# MKL02Z4 register map
Vendor: Freescale Semiconductor, Inc.; Series: Kinetis_L; File version: 1.6
CPU: CM0PLUS r0p0, little endian, no MPU, no FPU, VTOR, 2 interrupt priority bits
Registers are 32-bit, read-write, reset 0x0 unless marked. A register's access mark holds for its fields unless they carry their own. Offsets are from the block's base; [hi:lo] are bit positions; {n}, {i} and the like mark numbered series; 'fields as' and 'values as' point back to an identical list.

## PORTB — Pin Control and Interrupts
Base 0x4004A000; register names take the prefix PORTB_
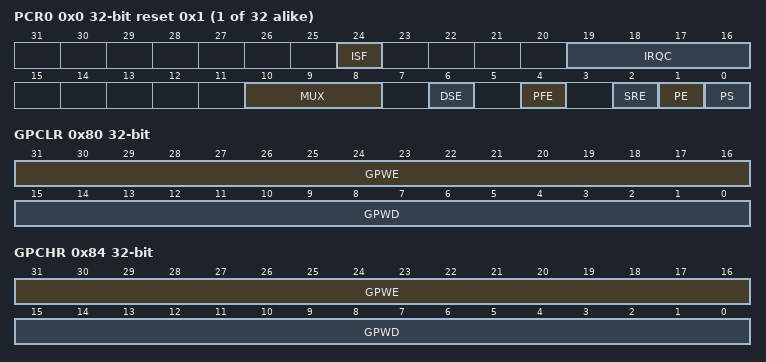
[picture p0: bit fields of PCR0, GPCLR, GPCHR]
{0x0+4i} PCR{i} (i=0..31) reset 0x1 — Pin Control Register n
  [24] ISF — Interrupt Status Flag
    0=Configured interrupt is not detected; 1=Configured interrupt is detected. The flag remains set until a logic one is written to the flag. If the pin is configured for a level sensitive interrupt and the pin remains asserted, then the flag is set again immediately after it is cleared.
  [19:16] IRQC — Interrupt Configuration
    0=Interrupt request disabled; 8=Interrupt when logic zero; 9=Interrupt on rising edge; 10=Interrupt on falling edge; 11=Interrupt on either edge; 12=Interrupt when logic one
  [10:8] MUX — Pin Mux Control
    0=Pin disabled (analog); 1=Alternative 1 (GPIO); {v}=Alternative {v} (chip-specific) (v=2..7)
  [6] DSE — Drive Strength Enable
    0=Low drive strength is configured on the corresponding pin, if pin is configured as a digital output; 1=High drive strength is configured on the corresponding pin, if pin is configured as a digital output
  [4] PFE — Passive Filter Enable
    0=Passive input filter is disabled on the corresponding pin; 1=Passive input filter is enabled on the corresponding pin, if the pin is configured as a digital input. Refer to the device data sheet for filter characteristics.
  [2] SRE — Slew Rate Enable
    0=Fast slew rate is configured on the corresponding pin, if the pin is configured as a digital output; 1=Slow slew rate is configured on the corresponding pin, if the pin is configured as a digital output
  [1] PE — Pull Enable
    0=Internal pullup or pulldown resistor is not enabled on the corresponding pin; 1=Internal pullup or pulldown resistor is enabled on the corresponding pin, if the pin is configured as a digital input
  [0] PS — Pull Select
    0=Internal pulldown resistor is enabled on the corresponding pin, if the corresponding Port Pull Enable field is set; 1=Internal pullup resistor is enabled on the corresponding pin, if the corresponding Port Pull Enable field is set
0x80 GPCLR wo — Global Pin Control Low Register
  [31:16] GPWE — Global Pin Write Enable
    0=Corresponding Pin Control Register is not updated with the value in GPWD; 1=Corresponding Pin Control Register is updated with the value in GPWD
  [15:0] GPWD — Global Pin Write Data
0x84 GPCHR wo — Global Pin Control High Register
  fields as GPCLR
0xA0 ISFR — Interrupt Status Flag Register
  [31:0] ISF — Interrupt Status Flag
    values as PCR0.ISF

## OSC0 — Oscillator
Base 0x40065000; register names take the prefix OSC0_
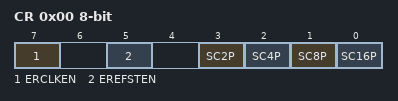
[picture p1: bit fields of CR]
0x00 CR 8-bit — OSC Control Register
  [7] ERCLKEN — External Reference Enable
    0=External reference clock is inactive; 1=External reference clock is enabled
  [5] EREFSTEN — External Reference Stop Enable
    0=External reference clock is disabled in Stop mode; 1=External reference clock stays enabled in Stop mode if ERCLKEN is set before entering Stop mode
  [3] SC2P — Oscillator 2 pF Capacitor Load Configure
    0=Disable the selection; 1=Add 2 pF capacitor to the oscillator load
  [2] SC4P — Oscillator 4 pF Capacitor Load Configure
    0=Disable the selection; 1=Add 4 pF capacitor to the oscillator load
  [1] SC8P — Oscillator 8 pF Capacitor Load Configure
    0=Disable the selection; 1=Add 8 pF capacitor to the oscillator load
  [0] SC16P — Oscillator 16 pF Capacitor Load Configure
    0=Disable the selection; 1=Add 16 pF capacitor to the oscillator load

## I2C0 — Inter-Integrated Circuit
Base 0x40066000; register names take the prefix I2C0_
0x00 A1 8-bit — I2C Address Register 1
  [7:1] AD — Address
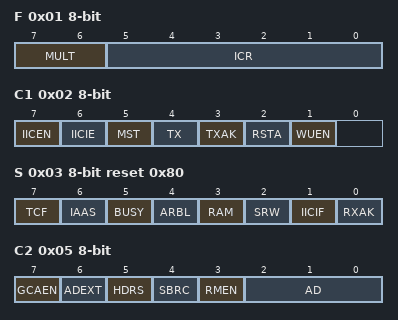
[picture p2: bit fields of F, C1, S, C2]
0x01 F 8-bit — I2C Frequency Divider register
  [7:6] MULT
    0=mul = 1; 1=mul = 2; 2=mul = 4
  [5:0] ICR — ClockRate
0x02 C1 8-bit — I2C Control Register 1
  [7] IICEN — I2C Enable
    0=Disabled; 1=Enabled
  [6] IICIE — I2C Interrupt Enable
    0=Disabled; 1=Enabled
  [5] MST — Master Mode Select
    0=Slave mode; 1=Master mode
  [4] TX — Transmit Mode Select
    0=Receive; 1=Transmit
  [3] TXAK — Transmit Acknowledge Enable
    0=An acknowledge signal is sent to the bus on the following receiving byte; 1=No acknowledge signal is sent to the bus on the following receiving data byte
  [2] RSTA wo — Repeat START
  [1] WUEN — Wakeup Enable
    0=Normal operation. No interrupt generated when address matching in low power mode.; 1=Enables the wakeup function in low power mode
0x03 S 8-bit reset 0x80 — I2C Status register
  [7] TCF ro — Transfer Complete Flag
    0=Transfer in progress; 1=Transfer complete
  [6] IAAS — Addressed As A Slave
    0=Not addressed; 1=Addressed as a slave
  [5] BUSY ro — Bus Busy
    0=Bus is idle; 1=Bus is busy
  [4] ARBL — Arbitration Lost
    0=Standard bus operation; 1=Loss of arbitration
  [3] RAM — Range Address Match
    0=Not addressed; 1=Addressed as a slave
  [2] SRW ro — Slave Read/Write
    0=Slave receive, master writing to slave; 1=Slave transmit, master reading from slave
  [1] IICIF — Interrupt Flag
    0=No interrupt pending; 1=Interrupt pending
  [0] RXAK ro — Receive Acknowledge
    0=Acknowledge signal was received after the completion of one byte of data transmission on the bus; 1=No acknowledge signal detected
0x04 D 8-bit — I2C Data I/O register
  [7:0] DATA
0x05 C2 8-bit — I2C Control Register 2
  [7] GCAEN — General Call Address Enable
    0=Disabled; 1=Enabled
  [6] ADEXT — Address Extension
    0=7-bit address scheme; 1=10-bit address scheme
  [5] HDRS — High Drive Select
    0=Normal drive mode; 1=High drive mode
  [4] SBRC — Slave Baud Rate Control
    0=The slave baud rate follows the master baud rate and clock stretching may occur; 1=Slave baud rate is independent of the master baud rate
  [3] RMEN — Range Address Matching Enable
    0=Range mode disabled. No address match occurs for an address within the range of values of the A1 and RA registers.; 1=Range mode enabled. Address matching occurs when a slave receives an address within the range of values of the A1 and RA registers.
  [2:0] AD — Slave Address
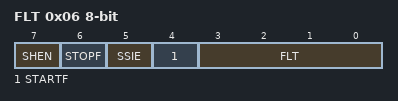
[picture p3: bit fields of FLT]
0x06 FLT 8-bit — I2C Programmable Input Glitch Filter register
  [7] SHEN — Stop Hold Enable
    0=Stop holdoff is disabled. The MCU's entry to stop mode is not gated.; 1=Stop holdoff is enabled
  [6] STOPF — I2C Bus Stop Detect Flag
    0=No stop happens on I2C bus; 1=Stop detected on I2C bus
  [5] SSIE — I2C Bus Stop or Start Interrupt Enable
    0=Stop or start detection interrupt is disabled; 1=Stop or start detection interrupt is enabled
  [4] STARTF — I2C Bus Start Detect Flag
    0=No start happens on I2C bus; 1=Start detected on I2C bus
  [3:0] FLT — I2C Programmable Filter Factor
    0=No filter/bypass
0x07 RA 8-bit — I2C Range Address register
  [7:1] RAD — Range Slave Address

## I2C1 — Inter-Integrated Circuit
Base 0x40067000; register names take the prefix I2C1_
Registers as I2C0.

## Notices in the file
Redistribution and use in source and binary forms, with or without modification,
are permitted provided that the following conditions are met:
o Redistributions of source code must retain the above copyright notice, this list
of conditions and the following disclaimer.
o Redistributions in binary form must reproduce the above copyright notice, this
list of conditions and the following disclaimer in the documentation and/or
other materials provided with the distribution.
o Neither the name of Freescale Semiconductor, Inc. nor the names of its
contributors may be used to endorse or promote products derived from this
software without specific prior written permission.
THIS SOFTWARE IS PROVIDED BY THE COPYRIGHT HOLDERS AND CONTRIBUTORS "AS IS" AND
ANY EXPRESS OR IMPLIED WARRANTIES, INCLUDING, BUT NOT LIMITED TO, THE IMPLIED
WARRANTIES OF MERCHANTABILITY AND FITNESS FOR A PARTICULAR PURPOSE ARE
DISCLAIMED. IN NO EVENT SHALL THE COPYRIGHT HOLDER OR CONTRIBUTORS BE LIABLE FOR
ANY DIRECT, INDIRECT, INCIDENTAL, SPECIAL, EXEMPLARY, OR CONSEQUENTIAL DAMAGES
(INCLUDING, BUT NOT LIMITED TO, PROCUREMENT OF SUBSTITUTE GOODS OR SERVICES;
LOSS OF USE, DATA, OR PROFITS; OR BUSINESS INTERRUPTION) HOWEVER CAUSED AND ON
ANY THEORY OF LIABILITY, WHETHER IN CONTRACT, STRICT LIABILITY, OR TORT
(INCLUDING NEGLIGENCE OR OTHERWISE) ARISING IN ANY WAY OUT OF THE USE OF THIS
SOFTWARE, EVEN IF ADVISED OF THE POSSIBILITY OF SUCH DAMAGE.
